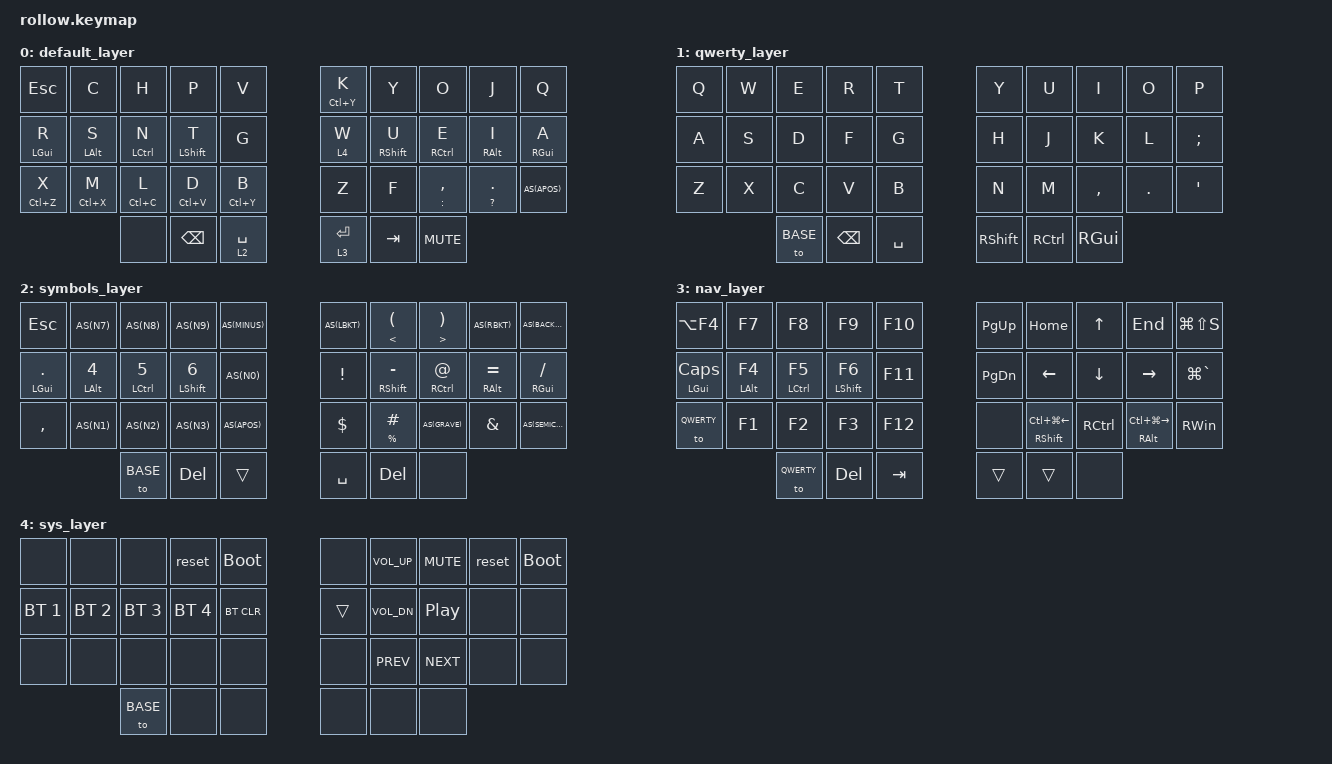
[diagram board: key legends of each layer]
/*
 * Copyright (c) 2020 The ZMK Contributors
 *
 * SPDX-License-Identifier: MIT
 */

#include <behaviors.dtsi>
#include <dt-bindings/zmk/keys.h>
#include <dt-bindings/zmk/bt.h>

#define BASE 0
#define QWERTY 1
#define SYMNUM 2
#define NAV 3
#define SYSMEDIA 4

#define AS(keycode) &as LS(keycode) keycode     // Autoshift Macro


&mt {
    tapping-term-ms = <200>;
};

/ {

  chosen {
    zmk,battery = &vbatt;
    zmk,matrix_transform = &five_column_transform;
  };

  vbatt: vbatt {
      compatible = "zmk,battery-nrf-vddh";
      label = "VBATT";
  };

  behaviors {
        as: auto_shift {
            compatible = "zmk,behavior-hold-tap";
            label = "AUTO_SHIFT";
            #binding-cells = <2>;
            tapping_term_ms = <190>;
            quick_tap_ms = <0>;
            flavor = "tap-preferred";
            bindings = <&kp>, <&kp>;
        };
        hm: home_row_mods {
            compatible = "zmk,behavior-hold-tap";
            label = "HOME_ROW_MODS";
            #binding-cells = <2>;
            tapping_term_ms = <190>;
            quick_tap_ms = <0>;
            flavor = "balanced";
            bindings = <&kp>, <&kp>;
        };
        th: tap_hold {
            compatible = "zmk,behavior-hold-tap";
            label = "TAP_HOLD";
            #binding-cells = <2>;
            tapping_term_ms = <190>;
            quick_tap_ms = <0>;
            flavor = "tap-preferred";
            bindings = <&kp>, <&kp>;
        };
    };

    combos {
     compatible = "zmk,combos";
        combo_ctrlbksp {
            timeout-ms = <50>;
            key-positions = <12 31>;
            bindings = <&kp LC(BSPC)>;
        };
        combo_snipping {
            timeout-ms = <50>;
            key-positions = <10 12 13>;
            bindings = <&kp LGUI(LS(S))>;
        };
    };

        keymap {
                compatible = "zmk,keymap";

                default_layer {
/* Default
 * .----------------------------------.                       .----------------------------------.
 * |  ESC |   C  |   H  |   P  |   V  |                       |   K  |   Y  |   o  |   J  |   Q  |
 * |------+------+------+------+------|                       |------+------+------+------+------|
 * |   A  |   S  |   D  |   F  |   G  |                       |   H  |   J  |   K  |   L  |   ;  |
 * |------+------+------+------+------|                       |------+------+------+------+------|
 * |   Z  |   X  |   C  |   V  |   B  | .-------.   .-------. |   N  |   M  |   ,  |   .  |   /  |
 * '----------------------------------'/       /     \       \'----------------------------------'
 *                   |  GUI |  LWR |  / Space /       \ Space \  |TT(RS)| Tab  |
 *                   |      |      | /       /         \       \ |      |      |
 *                   '-------------''-------'           '-------''-------------'
 *
 *   Encoder Left: Up <-> Down
 *   Encoder Right: Left <-> Right
 */
                        bindings = <
      &kp ESC           &kp C           &kp H           &kp P           &kp V                   &th LC(Y) K     &kp Y           &kp O              &kp J                &kp Q
      &hm LGUI R        &hm LALT S      &hm LCTRL N     &hm LSHFT T     &kp G                   &lt 4 W         &hm RSHFT U     &hm RCTRL E        &hm RALT I           &mt RGUI A
      &th LC(Z) X       &th LC(X) M     &th LC(C) L     &th LC(V) D     &th LC(Y) B             &kp Z           &kp F           &th COLON COMMA    &th QMARK PERIOD     AS(APOS)
                                        &none           &kp BSPC        &lt 2 SPACE             &lt 3 ENTER     &kp TAB         &kp C_MUTE

                        >;

                        sensor-bindings = <&inc_dec_kp LA(TAB) LA(LS(TAB)) &inc_dec_kp C_VOL_UP C_VOL_DN>;
                };


                qwerty_layer {
/* Default
 * .----------------------------------.                       .----------------------------------.
 * |   Q  |   W  |   E  |   R  |   T  |                       |   Y  |   U  |   I  |   O  |   P  |
 * |------+------+------+------+------|                       |------+------+------+------+------|
 * |   A  |   S  |   D  |   F  |   G  |                       |   H  |   J  |   K  |   L  |   ;  |
 * |------+------+------+------+------|                       |------+------+------+------+------|
 * |   Z  |   X  |   C  |   V  |   B  | .-------.   .-------. |   N  |   M  |   ,  |   .  |   /  |
 * '----------------------------------'/       /     \       \'----------------------------------'
 *                   |  GUI |  LWR |  / Space /       \ Space \  |TT(RS)| Tab  |
 *                   |      |      | /       /         \       \ |      |      |
 *                   '-------------''-------'           '-------''-------------'
 *
 *   Encoder Left: Up <-> Down
 *   Encoder Right: Left <-> Right
 */
                        bindings = <
      &kp Q             &kp W           &kp E           &kp R           &kp T                   &kp Y           &kp U           &kp I           &kp O           &kp P
      &kp A             &kp S           &kp D           &kp F           &kp G                   &kp H           &kp J           &kp K           &kp L           &kp SEMI
      &kp Z             &kp X           &kp C           &kp V           &kp B                   &kp N           &kp M           &kp COMMA       &kp PERIOD      &kp APOS
                                        &to BASE        &kp BSPC        &kp SPACE               &kp RSHFT       &kp RCTRL       &kp RGUI

                        >;

                        sensor-bindings = <&inc_dec_kp DOWN UP &inc_dec_kp RIGHT LEFT>;
                };


                symbols_layer {
/* Default
 * .----------------------------------.                       .----------------------------------.
 * |   Q  |   W  |   E  |   R  |   T  |                       |   Y  |   U  |   I  |   O  |   P  |
 * |------+------+------+------+------|                       |------+------+------+------+------|
 * |   A  |   S  |   D  |   F  |   G  |                       |   H  |   J  |   K  |   L  |   ;  |
 * |------+------+------+------+------|                       |------+------+------+------+------|
 * |   Z  |   X  |   C  |   V  |   B  | .-------.   .-------. |   N  |   M  |   ,  |   .  |   /  |
 * '----------------------------------'/       /     \       \'----------------------------------'
 *                   |  GUI |  LWR |  / Space /       \ Space \  |TT(RS)| Tab  |
 *                   |      |      | /       /         \       \ |      |      |
 *                   '-------------''-------'           '-------''-------------'
 *
 *   Encoder Left: Up <-> Down
 *   Encoder Right: Left <-> Right
 */
                        bindings = <
      &kp ESC           AS(N7)           AS(N8)           AS(N9)           AS(MINUS)              AS(LBKT)        &th LT LPAR     &th GT RPAR     AS(RBKT)        AS(BACKSLASH)
      &hm LGUI PERIOD   &hm LALT N4      &hm LCTRL N5     &hm LSHIFT N6    AS(N0)                 &kp EXCL        &hm RSHFT MINUS &hm RCTRL AT    &hm RALT EQUAL  &hm RGUI SLASH
      &kp COMMA         AS(N1)           AS(N2)           AS(N3)           AS(APOS)               &kp DOLLAR      &th PRCNT HASH  AS(GRAVE)       &kp AMPERSAND   AS(SEMICOLON)
                                         &to BASE         &kp DEL          &trans                 &kp SPACE       &kp DEL         &none

                        >;

                        sensor-bindings = <&inc_dec_kp DOWN UP &inc_dec_kp RIGHT LEFT>;
                };
                
                
                nav_layer {
/* Default
 * .----------------------------------.                       .----------------------------------.
 * |   Q  |   W  |   E  |   R  |   T  |                       |   Y  |   U  |   I  |   O  |   P  |
 * |------+------+------+------+------|                       |------+------+------+------+------|
 * |   A  |   S  |   D  |   F  |   G  |                       |   H  |   J  |   K  |   L  |   ;  |
 * |------+------+------+------+------|                       |------+------+------+------+------|
 * |   Z  |   X  |   C  |   V  |   B  | .-------.   .-------. |   N  |   M  |   ,  |   .  |   /  |
 * '----------------------------------'/       /     \       \'----------------------------------'
 *                   |  GUI |  LWR |  / Space /       \ Space \  |TT(RS)| Tab  |
 *                   |      |      | /       /         \       \ |      |      |
 *                   '-------------''-------'           '-------''-------------'
 *
 *   Encoder Left: Up <-> Down
 *   Encoder Right: Left <-> Right
 */
                        bindings = <
      &kp LA(F4)        &kp F7          &kp F8          &kp F9          &kp F10                 &kp PG_UP       &kp HOME               &kp UP          &kp END                &kp LG(LS(S))
      &hm LGUI CAPS     &hm LALT F4     &hm LCTRL F5    &hm LSHFT F6    &kp F11                 &kp PG_DN       &kp LEFT               &kp DOWN        &kp RIGHT              &kp LG(GRAVE)
      &to QWERTY        &kp F1          &kp F2          &kp F3          &kp F12                 &none           &th RSHFT LC(LG(LEFT)) &kp RCTRL       &th RALT LC(LG(RIGHT)) &kp RWIN
                                        &to QWERTY      &kp DEL         &kp TAB                 &trans          &trans                 &none

                        >;

                        sensor-bindings = <&inc_dec_kp LG(LC(RIGHT)) LG(LC(LEFT)) &inc_dec_kp C_VOL_DN C_VOL_UP>;
                };

                sys_layer {
/* Default
 * .----------------------------------.                       .----------------------------------.
 * |   Q  |   W  |   E  |   R  |   T  |                       |   Y  |   U  |   I  |   O  |   P  |
 * |------+------+------+------+------|                       |------+------+------+------+------|
 * |   A  |   S  |   D  |   F  |   G  |                       |   H  |   J  |   K  |   L  |   ;  |
 * |------+------+------+------+------|                       |------+------+------+------+------|
 * |   Z  |   X  |   C  |   V  |   B  | .-------.   .-------. |   N  |   M  |   ,  |   .  |   /  |
 * '----------------------------------'/       /     \       \'----------------------------------'
 *                   |  GUI |  LWR |  / Space /       \ Space \  |TT(RS)| Tab  |
 *                   |      |      | /       /         \       \ |      |      |
 *                   '-------------''-------'           '-------''-------------'
 *
 *   Encoder Left: Up <-> Down
 *   Encoder Right: Left <-> Right
 */
                        bindings = <
      &none             &none            &none            &reset           &bootloader            &none             &kp C_VOL_UP     &kp C_MUTE       &reset           &bootloader
      &bt BT_SEL 1      &bt BT_SEL 2     &bt BT_SEL 3     &bt BT_SEL 4     &bt BT_CLR             &trans            &kp C_VOL_DN     &kp C_PP         &none            &none
      &none             &none            &none            &none            &none                  &none             &kp C_PREV       &kp C_NEXT       &none            &none
                                         &to BASE         &none            &none                  &none             &none            &none

                        >;

                        sensor-bindings = <&inc_dec_kp DOWN UP &inc_dec_kp C_BRI_UP C_BRI_DEC>;
                };
                
        };
};
